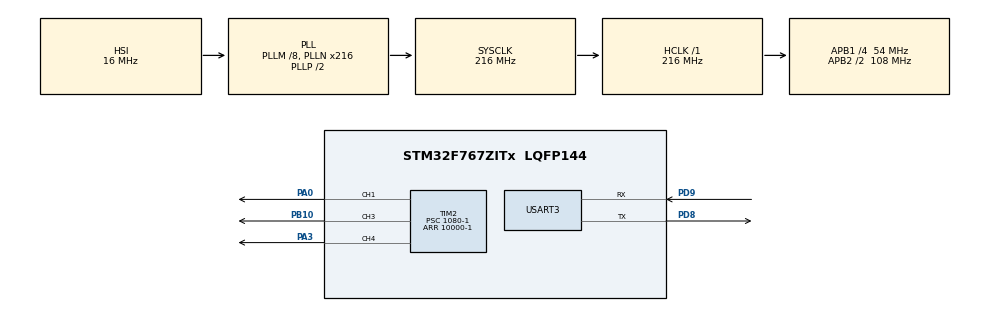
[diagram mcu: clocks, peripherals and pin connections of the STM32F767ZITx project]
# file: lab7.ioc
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Mcu.Family=STM32F7
Mcu.Name=STM32F767ZITx
Mcu.Package=LQFP144
NVIC.PriorityGroup=NVIC_PRIORITYGROUP_4
PA0/WKUP.GPIO_Speed=GPIO_SPEED_FREQ_VERY_HIGH
PA0/WKUP.Signal=S_TIM2_CH1_ETR
PA3.GPIO_Speed=GPIO_SPEED_FREQ_VERY_HIGH
PA3.Signal=S_TIM2_CH4
PB10.GPIO_Speed=GPIO_SPEED_FREQ_VERY_HIGH
PB10.Signal=S_TIM2_CH3
PD8.Mode=Asynchronous
PD8.Signal=USART3_TX
PD9.Mode=Asynchronous
PD9.Signal=USART3_RX
ProjectManager.HeapSize=0x200
ProjectManager.StackSize=0x400
ProjectManager.TargetToolchain=STM32CubeIDE
RCC.AHBFreq_Value=216000000
RCC.APB1CLKDivider=RCC_HCLK_DIV4
RCC.APB1Freq_Value=54000000
RCC.APB1TimFreq_Value=108000000
RCC.APB2CLKDivider=RCC_HCLK_DIV2
RCC.APB2Freq_Value=108000000
RCC.APB2TimFreq_Value=216000000
RCC.CortexFreq_Value=216000000
RCC.HCLKFreq_Value=216000000
RCC.HSE_VALUE=25000000
RCC.HSI_VALUE=16000000
RCC.LSE_VALUE=32768
RCC.PLLM=8
RCC.PLLN=216
RCC.SYSCLKFreq_VALUE=216000000
RCC.SYSCLKSource=RCC_SYSCLKSOURCE_PLLCLK
RCC.USBFreq_Value=216000000
RCC.VCOOutputFreq_Value=432000000
SH.S_TIM2_CH1_ETR.0=TIM2_CH1,PWM Generation1 CH1
SH.S_TIM2_CH3.0=TIM2_CH3,PWM Generation3 CH3
SH.S_TIM2_CH4.0=TIM2_CH4,PWM Generation4 CH4
TIM2.Channel-PWM\ Generation1\ CH1=TIM_CHANNEL_1
TIM2.Channel-PWM\ Generation3\ CH3=TIM_CHANNEL_3
TIM2.Channel-PWM\ Generation4\ CH4=TIM_CHANNEL_4
TIM2.Period=10000-1
TIM2.Prescaler=1080-1
TIM2.Pulse-PWM\ Generation3\ CH3=10000/4-1
USART3.VirtualMode-Asynchronous=VM_ASYNC
VP_TIM2_VS_ClockSourceINT.Mode=Internal
board=custom

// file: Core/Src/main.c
/* USER CODE BEGIN Header */
/**
  ******************************************************************************
  * @file           : main.c
  * @brief          : Main program body
  ******************************************************************************
  * @attention
  *
  * <h2><center>&copy; Copyright (c) 2021 STMicroelectronics.
  * All rights reserved.</center></h2>
  *
  * This software component is licensed by ST under BSD 3-Clause license,
  * the "License"; You may not use this file except in compliance with the
  * License. You may obtain a copy of the License at:
  *                        opensource.org/licenses/BSD-3-Clause
  *
  ******************************************************************************
  */
/* USER CODE END Header */
#include "main.h"
#include "tim.h"
#include "usart.h"
#include "gpio.h"

/* USER CODE BEGIN PV */
uint8_t pwm;
uint8_t pwm1;
uint8_t pwm2;
uint8_t pwm3;
char inputLabel[] ="Input => ";
char input;
char enter[] ="\r\n";
float dutyCycle =0.25;
float dutyCycleR =0.0;
float dutyCycleG =0.0;
float dutyCycleB =0.0;
uint8_t state=0;

/* USER CODE END PV */

void SystemClock_Config(void);

int main(void)
{

  /* MCU Configuration--------------------------------------------------------*/

  /* Reset of all peripherals, Initializes the Flash interface and the Systick. */
  HAL_Init();

  /* Configure the system clock */
  SystemClock_Config();

  /* Initialize all configured peripherals */
  MX_GPIO_Init();
  MX_TIM2_Init();
  MX_USART3_UART_Init();

  /* Infinite loop */
  while (1)
  {

    /* USER CODE BEGIN 3 */
	  /*HAL_TIM_PWM_Start(&htim2,TIM_CHANNEL_3);
	  HAL_Delay(100);
	  HAL_TIM_PWM_Stop(&htim2,TIM_CHANNEL_3);
	  pwm = (GPIOB->IDR & GPIO_PIN_10)>>10;*/

	  /*htim2.Instance -> CCR3 = (10000-1)*dutyCycle;
	  HAL_TIM_PWM_Start(&htim2,TIM_CHANNEL_3);
	  HAL_Delay(100);
	  HAL_TIM_PWM_Stop(&htim2,TIM_CHANNEL_3);
	  pwm = ((GPIOB->IDR & GPIO_PIN_10)>>10);*/

	  /*htim2.Instance -> CCR1 = (2000-1)*dutyCycleR;
	  htim2.Instance -> CCR4 = (2000-1)*dutyCycleG;
	  htim2.Instance -> CCR3 = (2000-1)*dutyCycleB;
	  HAL_TIM_PWM_Start(&htim2,TIM_CHANNEL_1);
	  HAL_TIM_PWM_Start(&htim2,TIM_CHANNEL_3);
	  HAL_TIM_PWM_Start(&htim2,TIM_CHANNEL_4);
	  pwm1 = ((GPIOA->IDR & GPIO_PIN_0)>>0);
	  pwm2 = ((GPIOA->IDR & GPIO_PIN_3)>>3);
	  pwm3 = ((GPIOB->IDR & GPIO_PIN_10)>>10);

	  while(__HAL_UART_GET_FLAG(&huart3,UART_FLAG_TC)==RESET){}
	  HAL_UART_Transmit(&huart3,(uint8_t*)inputLabel,strlen(inputLabel),1000);
	  while(__HAL_UART_GET_FLAG(&huart3,UART_FLAG_RXNE)==RESET){}
	  HAL_UART_Receive(&huart3,(uint8_t*)&input, sizeof(input), 1000);
	  while(__HAL_UART_GET_FLAG(&huart3,UART_FLAG_TC)==RESET){}
	  HAL_UART_Transmit(&huart3,(uint8_t*)&input,sizeof(input),1000);
	  while(__HAL_UART_GET_FLAG(&huart3,UART_FLAG_TC)==RESET){}
	  HAL_UART_Transmit(&huart3,(uint8_t*)enter,strlen(enter),1000);

	  if(input=='r'){
		  if(dutyCycleR != 1.0) {
			  dutyCycleR +=0.2;
		  }
		  else dutyCycleR = 0.0;
	  }else if(input=='g'){
		  if(dutyCycleG != 1.0) dutyCycleG +=0.2;
		  else dutyCycleG = 0.0;
	  }else if(input=='b'){
		  if(dutyCycleB != 1.0) dutyCycleB +=0.2;
		  else dutyCycleB = 0.0;
	  }

	  HAL_TIM_PWM_Stop(&htim2,TIM_CHANNEL_1);
	  HAL_TIM_PWM_Stop(&htim2,TIM_CHANNEL_3);
	  HAL_TIM_PWM_Stop(&htim2,TIM_CHANNEL_4);*/

  }
  /* USER CODE END 3 */
}

void SystemClock_Config(void)
{
  RCC_OscInitTypeDef RCC_OscInitStruct = {0};
  RCC_ClkInitTypeDef RCC_ClkInitStruct = {0};
  RCC_PeriphCLKInitTypeDef PeriphClkInitStruct = {0};

  /** Configure the main internal regulator output voltage
  */
  __HAL_RCC_PWR_CLK_ENABLE();
  __HAL_PWR_VOLTAGESCALING_CONFIG(PWR_REGULATOR_VOLTAGE_SCALE1);
  /** Initializes the RCC Oscillators according to the specified parameters
  * in the RCC_OscInitTypeDef structure.
  */
  RCC_OscInitStruct.OscillatorType = RCC_OSCILLATORTYPE_HSI;
  RCC_OscInitStruct.HSIState = RCC_HSI_ON;
  RCC_OscInitStruct.HSICalibrationValue = RCC_HSICALIBRATION_DEFAULT;
  RCC_OscInitStruct.PLL.PLLState = RCC_PLL_ON;
  RCC_OscInitStruct.PLL.PLLSource = RCC_PLLSOURCE_HSI;
  RCC_OscInitStruct.PLL.PLLM = 8;
  RCC_OscInitStruct.PLL.PLLN = 216;
  RCC_OscInitStruct.PLL.PLLP = RCC_PLLP_DIV2;
  RCC_OscInitStruct.PLL.PLLQ = 2;
  RCC_OscInitStruct.PLL.PLLR = 2;
  if (HAL_RCC_OscConfig(&RCC_OscInitStruct) != HAL_OK)
  {
    Error_Handler();
  }
  /** Activate the Over-Drive mode
  */
  if (HAL_PWREx_EnableOverDrive() != HAL_OK)
  {
    Error_Handler();
  }
  /** Initializes the CPU, AHB and APB buses clocks
  */
  RCC_ClkInitStruct.ClockType = RCC_CLOCKTYPE_HCLK|RCC_CLOCKTYPE_SYSCLK
                              |RCC_CLOCKTYPE_PCLK1|RCC_CLOCKTYPE_PCLK2;
  RCC_ClkInitStruct.SYSCLKSource = RCC_SYSCLKSOURCE_PLLCLK;
  RCC_ClkInitStruct.AHBCLKDivider = RCC_SYSCLK_DIV1;
  RCC_ClkInitStruct.APB1CLKDivider = RCC_HCLK_DIV4;
  RCC_ClkInitStruct.APB2CLKDivider = RCC_HCLK_DIV2;

  if (HAL_RCC_ClockConfig(&RCC_ClkInitStruct, FLASH_LATENCY_7) != HAL_OK)
  {
    Error_Handler();
  }
  PeriphClkInitStruct.PeriphClockSelection = RCC_PERIPHCLK_USART3;
  PeriphClkInitStruct.Usart3ClockSelection = RCC_USART3CLKSOURCE_PCLK1;
  if (HAL_RCCEx_PeriphCLKConfig(&PeriphClkInitStruct) != HAL_OK)
  {
    Error_Handler();
  }
}

void Error_Handler(void)
{
  __disable_irq();
  while (1)
  {
  }
}

/************************ (C) COPYRIGHT STMicroelectronics *****END OF FILE****/
